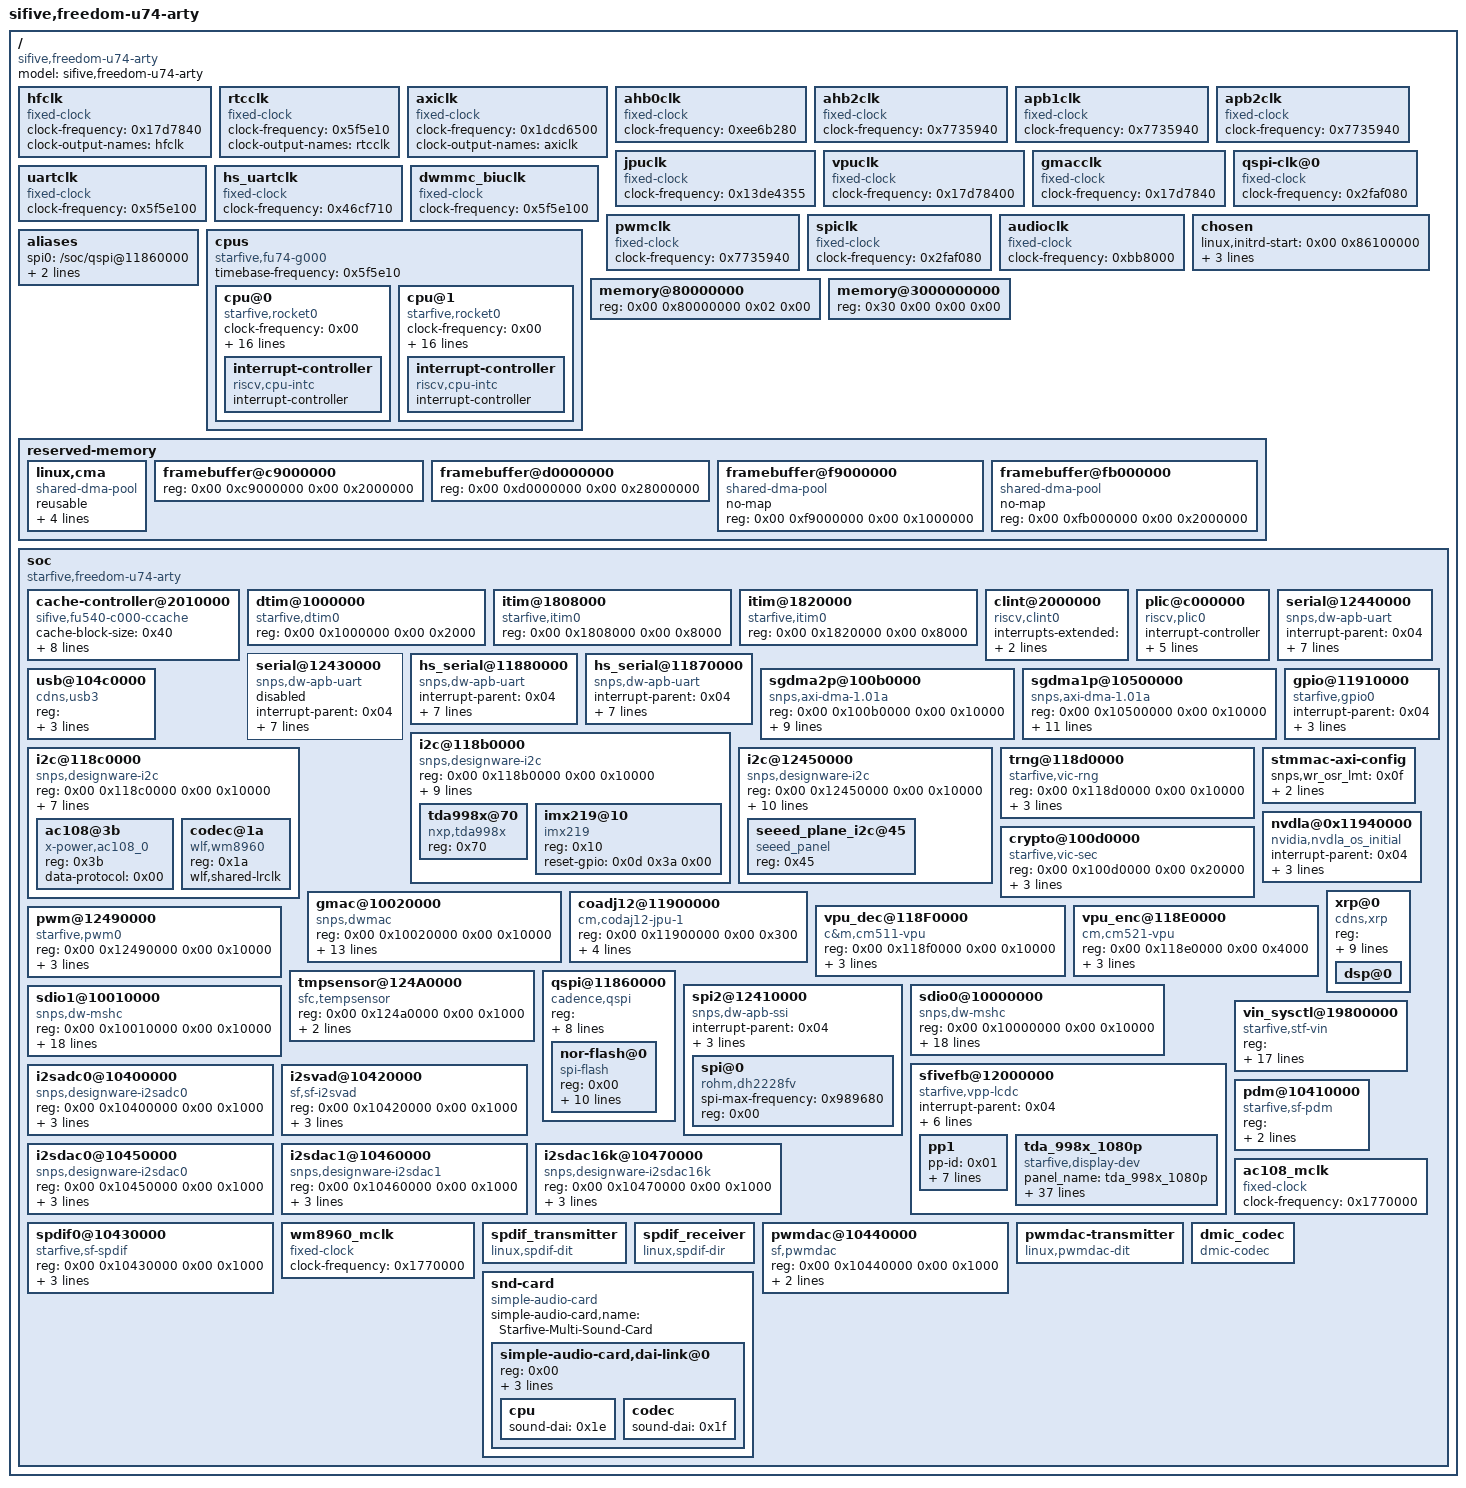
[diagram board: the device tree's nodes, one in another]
/dts-v1/;

/ {
	#address-cells = <0x02>;
	#size-cells = <0x02>;
	compatible = "sifive,freedom-u74-arty";
	model = "sifive,freedom-u74-arty";

	hfclk {
		#clock-cells = <0x00>;
		compatible = "fixed-clock";
		clock-frequency = <0x17d7840>;
		clock-output-names = "hfclk";
		phandle = <0x0e>;
	};

	rtcclk {
		#clock-cells = <0x00>;
		compatible = "fixed-clock";
		clock-frequency = <0x5f5e10>;
		clock-output-names = "rtcclk";
	};

	axiclk {
		#clock-cells = <0x00>;
		compatible = "fixed-clock";
		clock-frequency = <0x1dcd6500>;
		clock-output-names = "axiclk";
		phandle = <0x0b>;
	};

	ahb0clk {
		#clock-cells = <0x00>;
		compatible = "fixed-clock";
		clock-frequency = <0xee6b280>;
		phandle = <0x0c>;
	};

	ahb2clk {
		#clock-cells = <0x00>;
		compatible = "fixed-clock";
		clock-frequency = <0x7735940>;
	};

	apb1clk {
		#clock-cells = <0x00>;
		compatible = "fixed-clock";
		clock-frequency = <0x7735940>;
		phandle = <0x0a>;
	};

	apb2clk {
		#clock-cells = <0x00>;
		compatible = "fixed-clock";
		clock-frequency = <0x7735940>;
		phandle = <0x08>;
	};

	jpuclk {
		#clock-cells = <0x00>;
		compatible = "fixed-clock";
		clock-frequency = <0x13de4355>;
		phandle = <0x13>;
	};

	vpuclk {
		#clock-cells = <0x00>;
		compatible = "fixed-clock";
		clock-frequency = <0x17d78400>;
		phandle = <0x14>;
	};

	gmacclk {
		#clock-cells = <0x00>;
		compatible = "fixed-clock";
		clock-frequency = <0x17d7840>;
		phandle = <0x0f>;
	};

	qspi-clk@0 {
		#clock-cells = <0x00>;
		compatible = "fixed-clock";
		clock-frequency = <0x2faf080>;
		phandle = <0x16>;
	};

	uartclk {
		#clock-cells = <0x00>;
		compatible = "fixed-clock";
		clock-frequency = <0x5f5e100>;
		phandle = <0x07>;
	};

	hs_uartclk {
		#clock-cells = <0x00>;
		compatible = "fixed-clock";
		clock-frequency = <0x46cf710>;
		phandle = <0x09>;
	};

	dwmmc_biuclk {
		#clock-cells = <0x00>;
		compatible = "fixed-clock";
		clock-frequency = <0x5f5e100>;
		phandle = <0x18>;
	};

	pwmclk {
		#clock-cells = <0x00>;
		compatible = "fixed-clock";
		clock-frequency = <0x7735940>;
		phandle = <0x15>;
	};

	spiclk {
		#clock-cells = <0x00>;
		compatible = "fixed-clock";
		clock-frequency = <0x2faf080>;
		phandle = <0x17>;
	};

	audioclk {
		#clock-cells = <0x00>;
		compatible = "fixed-clock";
		clock-frequency = <0xbb8000>;
		phandle = <0x1c>;
	};

	chosen {
		linux,initrd-start = <0x00 0x86100000>;
		linux,initrd-end = <0x00 0x8c000000>;
		stdout-path = "/soc/serial@12440000:115200";
		#bootargs = "debug console=ttyS0 rootwait";
	};

	aliases {
		spi0 = "/soc/qspi@11860000";
		mshc0 = "/soc/sdio0@10000000";
		usb0 = "/soc/usb@104c0000";
	};

	cpus {
		#address-cells = <0x01>;
		#size-cells = <0x00>;
		timebase-frequency = <0x5f5e10>;
		compatible = "starfive,fu74-g000";

		cpu@0 {
			clock-frequency = <0x00>;
			compatible = "starfive,rocket0", "riscv";
			d-cache-block-size = <0x40>;
			d-cache-sets = <0x40>;
			d-cache-size = <0x8000>;
			d-tlb-sets = <0x01>;
			d-tlb-size = <0x20>;
			device_type = "cpu";
			i-cache-block-size = <0x40>;
			i-cache-sets = <0x40>;
			i-cache-size = <0x8000>;
			i-tlb-sets = <0x01>;
			i-tlb-size = <0x20>;
			mmu-type = "riscv,sv39";
			next-level-cache = <0x01>;
			reg = <0x00>;
			riscv,isa = "rv64imafdc";
			starfive,itim = <0x02>;
			status = "okay";
			tlb-split;

			interrupt-controller {
				#interrupt-cells = <0x01>;
				compatible = "riscv,cpu-intc";
				interrupt-controller;
				phandle = <0x05>;
			};
		};

		cpu@1 {
			clock-frequency = <0x00>;
			compatible = "starfive,rocket0", "riscv";
			d-cache-block-size = <0x40>;
			d-cache-sets = <0x40>;
			d-cache-size = <0x8000>;
			d-tlb-sets = <0x01>;
			d-tlb-size = <0x20>;
			device_type = "cpu";
			i-cache-block-size = <0x40>;
			i-cache-sets = <0x40>;
			i-cache-size = <0x8000>;
			i-tlb-sets = <0x01>;
			i-tlb-size = <0x20>;
			mmu-type = "riscv,sv39";
			next-level-cache = <0x01>;
			reg = <0x01>;
			riscv,isa = "rv64imafdc";
			starfive,itim = <0x03>;
			status = "okay";
			tlb-split;

			interrupt-controller {
				#interrupt-cells = <0x01>;
				compatible = "riscv,cpu-intc";
				interrupt-controller;
				phandle = <0x06>;
			};
		};
	};

	memory@80000000 {
		device_type = "memory";
		reg = <0x00 0x80000000 0x02 0x00>;
	};

	memory@3000000000 {
		device_type = "memory";
		reg = <0x30 0x00 0x00 0x00>;
	};

	reserved-memory {
		#address-cells = <0x02>;
		#size-cells = <0x02>;
		ranges;

		linux,cma {
			compatible = "shared-dma-pool";
			reusable;
			size = <0x00 0x28000000>;
			alignment = <0x00 0x1000>;
			alloc-ranges = <0x00 0xa0000000 0x00 0x28000000>;
			linux,cma-default;
		};

		framebuffer@c9000000 {
			reg = <0x00 0xc9000000 0x00 0x2000000>;
			phandle = <0x12>;
		};

		framebuffer@d0000000 {
			reg = <0x00 0xd0000000 0x00 0x28000000>;
			phandle = <0x11>;
		};

		framebuffer@f9000000 {
			compatible = "shared-dma-pool";
			no-map;
			reg = <0x00 0xf9000000 0x00 0x1000000>;
			phandle = <0x1a>;
		};

		framebuffer@fb000000 {
			compatible = "shared-dma-pool";
			no-map;
			reg = <0x00 0xfb000000 0x00 0x2000000>;
			phandle = <0x19>;
		};
	};

	soc {
		#address-cells = <0x02>;
		#size-cells = <0x02>;
		#clock-cells = <0x01>;
		compatible = "starfive,freedom-u74-arty", "simple-bus";
		ranges;

		cache-controller@2010000 {
			cache-block-size = <0x40>;
			cache-level = <0x02>;
			cache-sets = <0x800>;
			cache-size = <0x200000>;
			cache-unified;
			compatible = "sifive,fu540-c000-ccache", "starfive,ccache0", "cache";
			interrupt-parent = <0x04>;
			interrupts = <0x01 0x02 0x03>;
			reg = <0x00 0x2010000 0x00 0x1000 0x00 0x8000000 0x00 0x2000000>;
			reg-names = "control", "sideband";
			phandle = <0x01>;
		};

		dtim@1000000 {
			compatible = "starfive,dtim0";
			reg = <0x00 0x1000000 0x00 0x2000>;
			reg-names = "mem";
		};

		itim@1808000 {
			compatible = "starfive,itim0";
			reg = <0x00 0x1808000 0x00 0x8000>;
			reg-names = "mem";
			phandle = <0x02>;
		};

		itim@1820000 {
			compatible = "starfive,itim0";
			reg = <0x00 0x1820000 0x00 0x8000>;
			reg-names = "mem";
			phandle = <0x03>;
		};

		clint@2000000 {
			#interrupt-cells = <0x01>;
			compatible = "riscv,clint0";
			interrupts-extended = <0x05 0x03 0x05 0x07 0x06 0x03 0x06 0x07>;
			reg = <0x00 0x2000000 0x00 0x10000>;
			reg-names = "control";
		};

		plic@c000000 {
			#interrupt-cells = <0x01>;
			compatible = "riscv,plic0";
			interrupt-controller;
			interrupts-extended = <0x05 0x0b 0x05 0x09 0x06 0x0b 0x06 0x09>;
			reg = <0x00 0xc000000 0x00 0x4000000>;
			reg-names = "control";
			riscv,max-priority = <0x07>;
			riscv,ndev = <0x7f>;
			phandle = <0x04>;
		};

		serial@12440000 {
			compatible = "snps,dw-apb-uart";
			interrupt-parent = <0x04>;
			interrupts = <0x49>;
			reg = <0x00 0x12440000 0x00 0x10000>;
			reg-io-width = <0x04>;
			reg-shift = <0x02>;
			clocks = <0x07 0x08>;
			clock-names = "baudclk", "apb_pclk";
			current-clock = <0x5f5e100>;
			current-speed = <0x1c200>;
			status = "okay";
		};

		serial@12430000 {
			compatible = "snps,dw-apb-uart";
			interrupt-parent = <0x04>;
			interrupts = <0x48>;
			reg = <0x00 0x12430000 0x00 0x10000>;
			reg-io-width = <0x04>;
			reg-shift = <0x02>;
			clocks = <0x07 0x08>;
			clock-names = "baudclk", "apb_pclk";
			current-clock = <0x5f5e100>;
			current-speed = <0x1c200>;
			status = "disabled";
		};

		hs_serial@11880000 {
			compatible = "snps,dw-apb-uart";
			interrupt-parent = <0x04>;
			interrupts = <0x5d>;
			reg = <0x00 0x11880000 0x00 0x10000>;
			reg-io-width = <0x04>;
			reg-shift = <0x02>;
			clocks = <0x09 0x0a>;
			clock-names = "baudclk", "apb_pclk";
			current-clock = <0x46cf710>;
			current-speed = <0x1c200>;
			status = "okay";
		};

		hs_serial@11870000 {
			compatible = "snps,dw-apb-uart";
			interrupt-parent = <0x04>;
			interrupts = <0x5c>;
			reg = <0x00 0x11870000 0x00 0x10000>;
			reg-io-width = <0x04>;
			reg-shift = <0x02>;
			clocks = <0x09 0x0a>;
			clock-names = "baudclk", "apb_pclk";
			current-clock = <0x46cf710>;
			current-speed = <0x1c200>;
			status = "okay";
		};

		sgdma2p@100b0000 {
			compatible = "snps,axi-dma-1.01a";
			reg = <0x00 0x100b0000 0x00 0x10000>;
			clocks = <0x0b 0x0c>;
			clock-names = "core-clk", "cfgr-clk";
			interrupt-parent = <0x04>;
			interrupts = <0x02>;
			#dma-cells = <0x01>;
			dma-channels = <0x04>;
			snps,dma-masters = <0x01>;
			snps,data-width = <0x04>;
			snps,block-size = <0x1000 0x1000 0x1000 0x1000>;
			snps,priority = <0x00 0x01 0x02 0x03>;
			snps,axi-max-burst-len = <0x80>;
			status = "okay";
			phandle = <0x1b>;
		};

		sgdma1p@10500000 {
			compatible = "snps,axi-dma-1.01a";
			reg = <0x00 0x10500000 0x00 0x10000>;
			clocks = <0x0b 0x0c>;
			clock-names = "core-clk", "cfgr-clk";
			interrupt-parent = <0x04>;
			interrupts = <0x01>;
			#dma-cells = <0x01>;
			dma-channels = <0x10>;
			snps,dma-masters = <0x01>;
			snps,data-width = <0x03>;
			snps,block-size = <0x1000 0x1000 0x1000 0x1000 0x1000 0x1000 0x1000 0x1000 0x1000 0x1000 0x1000 0x1000 0x1000 0x1000 0x1000 0x1000>;
			snps,priority = <0x00 0x01 0x02 0x03 0x04 0x05 0x06 0x07 0x08 0x09 0x0a 0x0b 0x0c 0x0d 0x0e 0x0f>;
			snps,axi-max-burst-len = <0x40>;
			status = "okay";
		};

		usb@104c0000 {
			compatible = "cdns,usb3";
			reg = <0x00 0x104c0000 0x00 0x10000 0x00 0x104d0000 0x00 0x10000 0x00 0x104e0000 0x00 0x10000>;
			reg-names = "otg", "xhci", "dev";
			interrupt-parent = <0x04>;
			interrupts = <0x2b 0x2c 0x34>;
			interrupt-names = "otg", "host", "peripheral";
			phy-names = "cdns3,usb3-phy", "cnds3,usb2-phy";
			status = "okay";
		};

		gpio@11910000 {
			compatible = "starfive,gpio0";
			interrupt-parent = <0x04>;
			interrupts = <0x20>;
			reg = <0x00 0x11910000 0x00 0x10000>;
			reg-names = "control";
			interrupt-controller;
			#gpio-cells = <0x02>;
			phandle = <0x0d>;
		};

		i2c@118b0000 {
			#address-cells = <0x01>;
			#size-cells = <0x00>;
			compatible = "snps,designware-i2c";
			reg = <0x00 0x118b0000 0x00 0x10000>;
			interrupt-parent = <0x04>;
			interrupts = <0x60>;
			clock-frequency = <0x186a0>;
			i2c-sda-hold-time-ns = <0x12c>;
			i2c-sda-falling-time-ns = <0xbb8>;
			i2c-scl-falling-time-ns = <0xbb8>;
			auto_calc_scl_lhcnt;
			scl-gpio = <0x0d 0x3e 0x00>;
			sda-gpio = <0x0d 0x3d 0x00>;

			tda998x@70 {
				compatible = "nxp,tda998x";
				reg = <0x70>;
			};

			imx219@10 {
				compatible = "imx219";
				reg = <0x10>;
				reset-gpio = <0x0d 0x3a 0x00>;
			};
		};

		i2c@118c0000 {
			#address-cells = <0x01>;
			#size-cells = <0x00>;
			compatible = "snps,designware-i2c";
			reg = <0x00 0x118c0000 0x00 0x10000>;
			interrupt-parent = <0x04>;
			interrupts = <0x61>;
			clocks = <0x2f34f60>;
			clock-frequency = <0x61a80>;
			i2c-sda-hold-time-ns = <0x12c>;
			i2c-sda-falling-time-ns = <0x64>;
			i2c-scl-falling-time-ns = <0x64>;

			ac108@3b {
				compatible = "x-power,ac108_0";
				reg = <0x3b>;
				#sound-dai-cells = <0x00>;
				data-protocol = <0x00>;
			};

			codec@1a {
				compatible = "wlf,wm8960";
				reg = <0x1a>;
				#sound-dai-cells = <0x00>;
				wlf,shared-lrclk;
			};
		};

		i2c@12450000 {
			#address-cells = <0x01>;
			#size-cells = <0x00>;
			compatible = "snps,designware-i2c";
			reg = <0x00 0x12450000 0x00 0x10000>;
			interrupt-parent = <0x04>;
			interrupts = <0x4a>;
			clocks = <0x2faf080>;
			clock-frequency = <0x186a0>;
			i2c-sda-hold-time-ns = <0x12c>;
			i2c-sda-falling-time-ns = <0x1f4>;
			i2c-scl-falling-time-ns = <0x1f4>;
			auto_calc_scl_lhcnt;
			scl-gpio = <0x0d 0x12 0x00>;
			sda-gpio = <0x0d 0x13 0x00>;

			seeed_plane_i2c@45 {
				compatible = "seeed_panel";
				reg = <0x45>;
			};
		};

		trng@118d0000 {
			compatible = "starfive,vic-rng";
			reg = <0x00 0x118d0000 0x00 0x10000>;
			interrupt-parent = <0x04>;
			interrupts = <0x62>;
			clocks = <0x0e>;
		};

		crypto@100d0000 {
			compatible = "starfive,vic-sec";
			reg = <0x00 0x100d0000 0x00 0x20000>;
			interrupt-parent = <0x04>;
			interrupts = <0x1f>;
			clocks = <0x0e>;
		};

		stmmac-axi-config {
			snps,wr_osr_lmt = <0x0f>;
			snps,rd_osr_lmt = <0x0f>;
			snps,blen = <0x100 0x80 0x40 0x20 0x00 0x00 0x00>;
			phandle = <0x10>;
		};

		gmac@10020000 {
			compatible = "snps,dwmac";
			reg = <0x00 0x10020000 0x00 0x10000>;
			interrupt-parent = <0x04>;
			interrupts = <0x06 0x07>;
			interrupt-names = "macirq", "eth_wake_irq";
			max-frame-size = <0x2328>;
			phy-mode = "rgmii-txid";
			snps,multicast-filter-bins = <0x100>;
			snps,perfect-filter-entries = <0x80>;
			rx-fifo-depth = <0x8000>;
			tx-fifo-depth = <0x4000>;
			clocks = <0x0f>;
			clock-names = "stmmaceth";
			snps,fixed-burst = <0x01>;
			snps,no-pbl-x8 = <0x01>;
			snps,force_thresh_dma_mode;
			snps,axi-config = <0x10>;
		};

		nvdla@0x11940000 {
			compatible = "nvidia,nvdla_os_initial";
			interrupt-parent = <0x04>;
			interrupts = <0x16>;
			memory-region = <0x11>;
			reg = <0x00 0x11940000 0x00 0x40000>;
			status = "okay";
		};

		coadj12@11900000 {
			compatible = "cm,codaj12-jpu-1";
			reg = <0x00 0x11900000 0x00 0x300>;
			memory-region = <0x12>;
			interrupt-parent = <0x04>;
			interrupts = <0x18>;
			clocks = <0x13>;
			clock-names = "jpege";
			reg-names = "control";
			status = "okay";
		};

		vpu_dec@118F0000 {
			compatible = "c&m,cm511-vpu";
			reg = <0x00 0x118f0000 0x00 0x10000>;
			interrupt-parent = <0x04>;
			interrupts = <0x17>;
			clocks = <0x14>;
			clock-names = "vcodec";
			status = "okay";
		};

		vpu_enc@118E0000 {
			compatible = "cm,cm521-vpu";
			reg = <0x00 0x118e0000 0x00 0x4000>;
			interrupt-parent = <0x04>;
			interrupts = <0x1a>;
			clocks = <0x14>;
			clock-names = "vcodec";
			reg-names = "control";
		};

		pwm@12490000 {
			compatible = "starfive,pwm0";
			reg = <0x00 0x12490000 0x00 0x10000>;
			reg-names = "control";
			sifive,approx-period = <0x5f5e100>;
			clocks = <0x15>;
			#pwm-cells = <0x03>;
			sifive,npwm = <0x08>;
		};

		tmpsensor@124A0000 {
			compatible = "sfc,tempsensor";
			reg = <0x00 0x124a0000 0x00 0x1000>;
			interrupt-parent = <0x04>;
			interrupts = <0x7a>;
			status = "okay";
		};

		qspi@11860000 {
			compatible = "cadence,qspi", "cdns,qspi-nor";
			#address-cells = <0x01>;
			#size-cells = <0x00>;
			reg = <0x00 0x11860000 0x00 0x10000 0x00 0x20000000 0x00 0x20000000>;
			interrupts = <0x03>;
			interrupt-parent = <0x04>;
			clocks = <0x16>;
			cdns,fifo-depth = <0x100>;
			cdns,fifo-width = <0x04>;
			cdns,trigger-address = <0x00>;
			status = "okay";
			spi-max-frequency = <0xee6b280>;

			nor-flash@0 {
				compatible = "spi-flash";
				reg = <0x00>;
				spi-max-frequency = <0x5f5e100>;
				page-size = <0x100>;
				block-size = <0x10>;
				cdns,read-delay = <0x04>;
				cdns,tshsl-ns = <0x01>;
				cdns,tsd2d-ns = <0x01>;
				cdns,tchsh-ns = <0x01>;
				cdns,tslch-ns = <0x01>;
				spi-tx-bus-width = <0x01>;
				spi-rx-bus-width = <0x01>;
			};
		};

		spi2@12410000 {
			compatible = "snps,dw-apb-ssi";
			#address-cells = <0x01>;
			#size-cells = <0x00>;
			interrupt-parent = <0x04>;
			interrupts = <0x46>;
			reg = <0x00 0x12410000 0x00 0x10000>;
			clocks = <0x17>;

			spi@0 {
				compatible = "rohm,dh2228fv";
				spi-max-frequency = <0x989680>;
				reg = <0x00>;
				status = "okay";
			};
		};

		xrp@0 {
			compatible = "cdns,xrp";
			reg = <0x00 0xf0000000 0x00 0x1ffffff 0x10 0x72000000 0x00 0x1000 0x10 0x72001000 0x00 0xfff000 0x00 0x124b0000 0x00 0x10000>;
			clocks = <0x0e>;
			interrupt-parent = <0x04>;
			firmware-name = "vp6_elf";
			dsp-irq = <0x13 0x14>;
			dsp-irq-src = <0x20 0x21>;
			intc-irq-mode = <0x01>;
			intc-irq = <0x00 0x01>;
			interrupts = <0x1b 0x1c>;
			#address-cells = <0x01>;
			#size-cells = <0x01>;
			ranges = <0x40000000 0x00 0x40000000 0x1000000 0xb0000000 0x10 0x70000000 0x3000000>;

			dsp@0 {
			};
		};

		sdio0@10000000 {
			compatible = "snps,dw-mshc";
			reg = <0x00 0x10000000 0x00 0x10000>;
			interrupts = <0x04>;
			interrupt-parent = <0x04>;
			clocks = <0x18>;
			clock-names = "biu";
			clock-frequency = <0x5f5e100>;
			max-frequency = <0x2faf080>;
			fifo-depth = <0x20>;
			card-detect-delay = <0x12c>;
			fifo-watermark-aligned;
			data-addr = <0x00>;
			bus-width = <0x04>;
			cap-sd-highspeed;
			cap-sdio-irq;
			cap-mmc-hw-reset;
			non-removable;
			enable-sdio-wakeup;
			keep-power-in-suspend;
			cap-mmc-highspeed;
			post-power-on-delay-ms = <0xc8>;
		};

		sdio1@10010000 {
			compatible = "snps,dw-mshc";
			reg = <0x00 0x10010000 0x00 0x10000>;
			interrupts = <0x05>;
			interrupt-parent = <0x04>;
			clocks = <0x18>;
			clock-names = "biu";
			clock-frequency = <0x5f5e100>;
			max-frequency = <0x18cba80>;
			fifo-depth = <0x20>;
			card-detect-delay = <0x12c>;
			fifo-watermark-aligned;
			data-addr = <0x00>;
			bus-width = <0x04>;
			cap-sd-highspeed;
			cap-sdio-irq;
			cap-mmc-hw-reset;
			non-removable;
			enable-sdio-wakeup;
			keep-power-in-suspend;
			cap-mmc-highspeed;
			post-power-on-delay-ms = <0xc8>;
		};

		sfivefb@12000000 {
			compatible = "starfive,vpp-lcdc";
			interrupt-parent = <0x04>;
			interrupts = <0x65 0x67>;
			interrupt-names = "lcdc_irq", "vpp1_irq";
			reg = <0x00 0x12000000 0x00 0x10000 0x00 0x12100000 0x00 0x10000 0x00 0x12040000 0x00 0x10000 0x00 0x12080000 0x00 0x10000 0x00 0x120c0000 0x00 0x10000 0x00 0x12240000 0x00 0x10000 0x00 0x12250000 0x00 0x10000 0x00 0x12260000 0x00 0x10000>;
			reg-names = "lcdc", "dsitx", "vpp0", "vpp1", "vpp2", "clk", "rst", "sys";
			memory-region = <0x19>;
			clocks = <0x07 0x08>;
			clock-names = "baudclk", "apb_pclk";
			status = "okay";
			ddr-format = <0x04>;

			pp1 {
				pp-id = <0x01>;
				fifo-out;
				src-format = <0x05>;
				src-width = <0x780>;
				src-height = <0x438>;
				dst-format = <0x07>;
				dst-width = <0x780>;
				dst-height = <0x438>;
			};

			tda_998x_1080p {
				compatible = "starfive,display-dev";
				panel_name = "tda_998x_1080p";
				panel_lcd_id = <0x16>;
				interface_info = "rgb_interface";
				refresh_en = <0x01>;
				bits-per-pixel = <0x10>;
				physical-width = <0x3e>;
				physical-height = <0x72>;
				panel-width = <0x780>;
				panel-height = <0x438>;
				pixel-clock = <0x4a62f80>;
				mipi-byte-clock = <0x130b0>;
				mipi-escape-clock = <0x32c8>;
				lane-no = <0x04>;
				display_mode = "video_mode";
				color_bits = <0x05>;
				h-pulse-width = <0x2c>;
				h-back-porch = <0x94>;
				h-front-porch = <0x58>;
				v-pulse-width = <0x05>;
				v-back-porch = <0x24>;
				v-front-porch = <0x04>;
				status = "okay";
				sync_pol = "vsync_high_act";
				lp_cmd_en;
				lp_vfp_en;
				lp_vbp_en;
				lp_vsa_en;
				traffic-mode = "burst_with_sync_pulses";
				data_tprepare = [00];
				data_hs_zero = [00];
				data_hs_exit = [00];
				data_hs_trail = [00];
				te_source = "external_pin";
				te_trigger_mode = "rising_edge";
				te_enable = <0x00>;
				cm_te_effect_sync_enable = <0x00>;
				te_count_per_sec = <0x40>;
				eotp_tx_en;
				dev_read_time = <0x7fff>;
			};
		};

		vin_sysctl@19800000 {
			compatible = "starfive,stf-vin";
			reg = <0x00 0x19800000 0x00 0x10000 0x00 0x19810000 0x00 0x10000 0x00 0x19820000 0x00 0x10000 0x00 0x19830000 0x00 0x10000 0x00 0x19840000 0x00 0x10000 0x00 0x19870000 0x00 0x30000 0x00 0x198a0000 0x00 0x30000 0x00 0x11800000 0x00 0x10000 0x00 0x11840000 0x00 0x10000 0x00 0x11858000 0x00 0x10000>;
			reg-names = "mipi0", "vclk", "vrst", "mipi1", "sctrl", "isp0", "isp1", "tclk", "trst", "iopad";
			interrupt-parent = <0x04>;
			interrupts = <0x77 0x6d>;
			memory-region = <0x1a>;
			format = <0x03>;
			frame-width = <0x780>;
			frame-height = <0x438>;
			isp0_enable;
			csi-lane = <0x02>;
			csi-dlane-swaps = <0x1020304>;
			csi-dlane-pn-swaps = <0x00>;
			csi-clane-swap = [00];
			csi-clane-pn-swap = [00];
			csi-mipiID = <0x00>;
			csi-width = <0x780>;
			csi-height = <0x438>;
			csi-dt = <0x2b>;
		};

		i2sadc0@10400000 {
			compatible = "snps,designware-i2sadc0";
			reg = <0x00 0x10400000 0x00 0x1000>;
			interrupt-parent = <0x04>;
			clocks = <0x0a>;
			clock-names = "i2sclk";
			#sound-dai-cells = <0x00>;
			dmas = <0x1b 0x1c>;
			dma-names = "rx";
		};

		i2svad@10420000 {
			compatible = "sf,sf-i2svad";
			reg = <0x00 0x10420000 0x00 0x1000>;
			interrupt-parent = <0x04>;
			interrupts = <0x3c 0x3d>;
			interrupt-names = "spintr", "slintr";
			clocks = <0x0a>;
			clock-names = "i2sclk";
			#sound-dai-cells = <0x00>;
		};

		i2sdac0@10450000 {
			compatible = "snps,designware-i2sdac0";
			reg = <0x00 0x10450000 0x00 0x1000>;
			interrupt-parent = <0x04>;
			clocks = <0x0a>;
			clock-names = "i2sclk";
			#sound-dai-cells = <0x00>;
			dmas = <0x1b 0x1e>;
			dma-names = "tx";
		};

		i2sdac1@10460000 {
			compatible = "snps,designware-i2sdac1";
			reg = <0x00 0x10460000 0x00 0x1000>;
			interrupt-parent = <0x04>;
			clocks = <0x0a>;
			clock-names = "i2sclk";
			#sound-dai-cells = <0x00>;
			dmas = <0x1b 0x1f>;
			dma-names = "tx";
		};

		i2sdac16k@10470000 {
			compatible = "snps,designware-i2sdac16k";
			reg = <0x00 0x10470000 0x00 0x1000>;
			interrupt-parent = <0x04>;
			clocks = <0x0a>;
			clock-names = "i2sclk";
			#sound-dai-cells = <0x00>;
			dmas = <0x1b 0x1d>;
			dma-names = "tx";
		};

		spdif0@10430000 {
			compatible = "starfive,sf-spdif";
			reg = <0x00 0x10430000 0x00 0x1000>;
			interrupt-parent = <0x04>;
			interrupts = <0x3e>;
			interrupt-names = "tx";
			clocks = <0x1c>;
			clock-names = "audioclk";
			#sound-dai-cells = <0x00>;
		};

		pdm@10410000 {
			compatible = "starfive,sf-pdm";
			reg = <0x00 0x10410000 0x00 0x1000 0x00 0x10480000 0x00 0x1000>;
			reg-names = "pdm", "audio-clk";
			clocks = <0x1c>;
			clock-names = "audioclk";
			#sound-dai-cells = <0x00>;
		};

		ac108_mclk {
			compatible = "fixed-clock";
			#clock-cells = <0x00>;
			clock-frequency = <0x1770000>;
		};

		wm8960_mclk {
			compatible = "fixed-clock";
			#clock-cells = <0x00>;
			clock-frequency = <0x1770000>;
		};

		spdif_transmitter {
			compatible = "linux,spdif-dit";
			#sound-dai-cells = <0x00>;
		};

		spdif_receiver {
			compatible = "linux,spdif-dir";
			#sound-dai-cells = <0x00>;
		};

		pwmdac@10440000 {
			compatible = "sf,pwmdac";
			reg = <0x00 0x10440000 0x00 0x1000>;
			clocks = <0x0a>;
			dmas = <0x1b 0x17>;
			dma-names = "tx";
			#sound-dai-cells = <0x00>;
			phandle = <0x1e>;
		};

		pwmdac-transmitter {
			compatible = "linux,pwmdac-dit";
			#sound-dai-cells = <0x00>;
			phandle = <0x1f>;
		};

		dmic_codec {
			compatible = "dmic-codec";
			#sound-dai-cells = <0x00>;
		};

		snd-card {
			compatible = "simple-audio-card";
			simple-audio-card,name = "Starfive-Multi-Sound-Card";

			simple-audio-card,dai-link@0 {
				reg = <0x00>;
				status = "okay";
				format = "left_j";
				bitclock-master = <0x1d>;
				frame-master = <0x1d>;

				cpu {
					sound-dai = <0x1e>;
					phandle = <0x1d>;
				};

				codec {
					sound-dai = <0x1f>;
				};
			};
		};
	};
};
